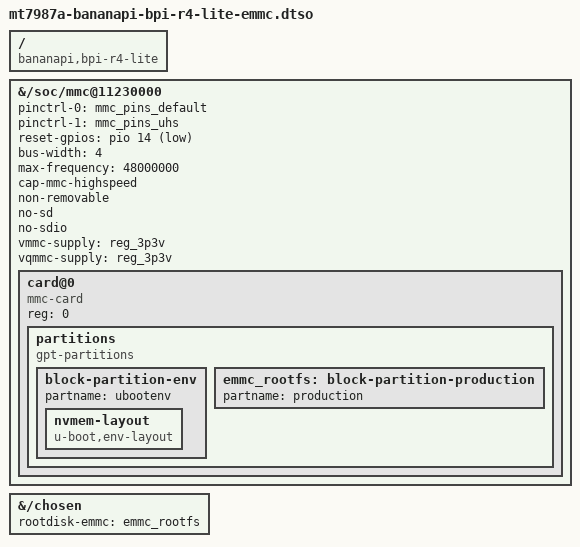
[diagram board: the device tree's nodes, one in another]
/dts-v1/;
/plugin/;

#include <dt-bindings/gpio/gpio.h>

/ {
	compatible = "bananapi,bpi-r4-lite",
		     "mediatek,mt7987a", "mediatek,mt7987";
};

&{/soc/mmc@11230000} {
	pinctrl-names = "default", "state_uhs";
	pinctrl-0 = <&mmc_pins_default>;
	pinctrl-1 = <&mmc_pins_uhs>;
	reset-gpios = <&pio 14 GPIO_ACTIVE_LOW>;

	bus-width = <4>; /* interference from shared DAT5<->SD-CD pin */
	max-frequency = <48000000>;
	cap-mmc-highspeed;
	non-removable;
	no-sd;
	no-sdio;
	vmmc-supply = <&reg_3p3v>;
	vqmmc-supply = <&reg_3p3v>;

	#address-cells = <1>;
	#size-cells = <0>;

	status = "okay";

	card@0 {
		compatible = "mmc-card";
		reg = <0>;

		partitions {
			compatible = "gpt-partitions";

			block-partition-env {
				partname = "ubootenv";
				nvmem-layout {
					compatible = "u-boot,env-layout";
				};
			};

			emmc_rootfs: block-partition-production {
				partname = "production";
			};
		};
	};
};

&{/chosen} {
	rootdisk-emmc = <&emmc_rootfs>;
};
